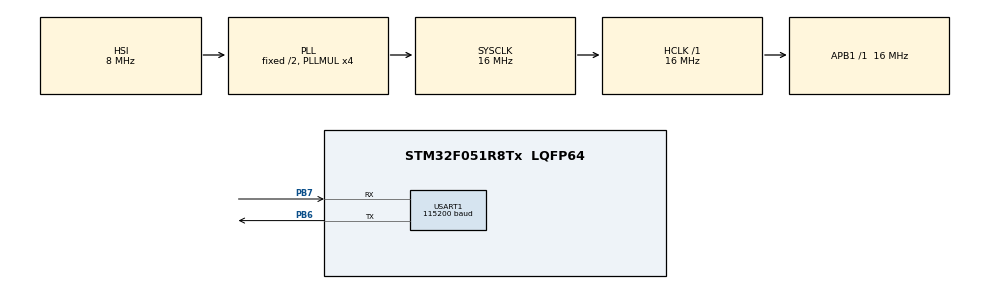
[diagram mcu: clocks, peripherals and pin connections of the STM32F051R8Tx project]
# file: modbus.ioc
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Mcu.Family=STM32F0
Dma.USART1_TX.1.Instance=DMA1_Channel2
Dma.USART1_RX.0.PeriphDataAlignment=DMA_PDATAALIGN_BYTE
Dma.USART1_TX.1.MemInc=DMA_MINC_ENABLE
USART1.BaudRate=115200
TIM6.Prescaler=15
VP_TIM6_VS_ClockSourceINT.Mode=Enable_Timer
RCC.SYSCLKSource=RCC_SYSCLKSOURCE_PLLCLK
ProjectManager.StackSize=0x200
USART1.VirtualMode-Asynchronous=VM_ASYNC
VP_SYS_VS_tim3.Mode=TIM3
ProjectManager.TargetToolchain=STM32CubeIDE
Dma.USART1_RX.0.Direction=DMA_PERIPH_TO_MEMORY
RCC.HCLKFreq_Value=16000000
USART1.Parity=PARITY_NONE
PB6.Signal=USART1_TX
PB6.Mode=Asynchronous
RCC.AHBFreq_Value=16000000
Dma.USART1_RX.0.Priority=DMA_PRIORITY_LOW
Dma.USART1_RX.0.PeriphInc=DMA_PINC_DISABLE
Dma.USART1_TX.1.MemDataAlignment=DMA_MDATAALIGN_BYTE
board=custom
RCC.PLLMUL=RCC_PLL_MUL4
NVIC.TIM3_IRQn=true\:0\:0\:false\:false\:true\:false\:true
USART1.OverrunDisableParam=ADVFEATURE_OVERRUN_DISABLE
Dma.USART1_RX.0.MemDataAlignment=DMA_MDATAALIGN_BYTE
PB7.Signal=USART1_RX
TIM6.Period=1
Dma.USART1_RX.0.MemInc=DMA_MINC_ENABLE
Mcu.Name=STM32F051R8Tx
Dma.USART1_TX.1.PeriphDataAlignment=DMA_PDATAALIGN_BYTE
RCC.SYSCLKFreq_VALUE=16000000
Mcu.Package=LQFP64
NVIC.TimeBase=TIM3_IRQn
Dma.USART1_TX.1.Mode=DMA_NORMAL
PB7.Mode=Asynchronous
NVIC.TimeBaseIP=TIM3
ProjectManager.HeapSize=0x50
Dma.USART1_TX.1.PeriphInc=DMA_PINC_DISABLE
USART1.DMADisableonRxErrorParam=ADVFEATURE_DMA_DISABLEONRXERROR
NVIC.DMA1_Channel2_3_IRQn=true\:0\:0\:false\:false\:true\:false\:true
RCC.APB1TimFreq_Value=16000000
Dma.Request1=USART1_TX
Dma.USART1_RX.0.Mode=DMA_NORMAL
Dma.USART1_TX.1.Priority=DMA_PRIORITY_LOW
NVIC.USART1_IRQn=true\:0\:0\:false\:false\:true\:true\:true
Dma.Request0=USART1_RX
RCC.APB1Freq_Value=16000000
Dma.USART1_RX.0.Instance=DMA1_Channel3
Dma.USART1_TX.1.Direction=DMA_MEMORY_TO_PERIPH

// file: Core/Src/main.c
/* USER CODE BEGIN Header */
/**
 ******************************************************************************
 * @file           : main.c
 * @brief          : Main program body
 ******************************************************************************
 * @attention
 *
 * <h2><center>&copy; Copyright (c) 2021 STMicroelectronics.
 * All rights reserved.</center></h2>
 *
 * This software component is licensed by ST under BSD 3-Clause license,
 * the "License"; You may not use this file except in compliance with the
 * License. You may obtain a copy of the License at:
 *                        opensource.org/licenses/BSD-3-Clause
 *
 ******************************************************************************
 */
/* USER CODE END Header */
#include "main.h"
#include "dma.h"
#include "tim.h"
#include "usart.h"
#include "gpio.h"

/* USER CODE BEGIN Includes */

#include "modbus.h"

/* USER CODE END Includes */

void SystemClock_Config(void);

int main(void)
{

  /* MCU Configuration--------------------------------------------------------*/

  /* Reset of all peripherals, Initializes the Flash interface and the Systick. */
  HAL_Init();

  /* Configure the system clock */
  SystemClock_Config();

  /* Initialize all configured peripherals */
  MX_GPIO_Init();
  MX_DMA_Init();
  MX_USART1_UART_Init();
  MX_TIM6_Init();
  /* USER CODE BEGIN 2 */

  initModbus();
  HAL_UARTEx_ReceiveToIdle_DMA(&huart1, mbBuffer, ASCII_FRAME_SIZE);

  SetHoldingRegisterValue_s16(50, -9999);
  SetHoldingRegisterValue_u16(1, 9998);
  SetHoldingRegisterValue_u32(10, 66888);
  SetHoldingRegisterValue_s32(11, -66888);
  SetHoldingRegisterValue_f32(12, 10.2134f);

  SetInputRegisterValue_s16(17, -9999);
  SetInputRegisterValue_u16(12, 9998);
  SetInputRegisterValue_u32(20, 66888);
  SetInputRegisterValue_s32(19, -66888);
  SetInputRegisterValue_f32(15, 10.2134f);
  /* USER CODE END 2 */

  /* Infinite loop */
  /* USER CODE BEGIN WHILE */
  while (1)
  {
    //SetHoldingRegisterValue_u32(24, GetHoldingRegisterValue_u32(10));
    HAL_Delay(100);
    /* USER CODE END WHILE */

  }
}

void SystemClock_Config(void)
{
  RCC_OscInitTypeDef RCC_OscInitStruct = {0};
  RCC_ClkInitTypeDef RCC_ClkInitStruct = {0};
  RCC_PeriphCLKInitTypeDef PeriphClkInit = {0};

  /** Initializes the RCC Oscillators according to the specified parameters
  * in the RCC_OscInitTypeDef structure.
  */
  RCC_OscInitStruct.OscillatorType = RCC_OSCILLATORTYPE_HSI;
  RCC_OscInitStruct.HSIState = RCC_HSI_ON;
  RCC_OscInitStruct.HSICalibrationValue = RCC_HSICALIBRATION_DEFAULT;
  RCC_OscInitStruct.PLL.PLLState = RCC_PLL_ON;
  RCC_OscInitStruct.PLL.PLLSource = RCC_PLLSOURCE_HSI;
  RCC_OscInitStruct.PLL.PLLMUL = RCC_PLL_MUL4;
  RCC_OscInitStruct.PLL.PREDIV = RCC_PREDIV_DIV1;
  if (HAL_RCC_OscConfig(&RCC_OscInitStruct) != HAL_OK)
  {
    Error_Handler();
  }
  /** Initializes the CPU, AHB and APB buses clocks
  */
  RCC_ClkInitStruct.ClockType = RCC_CLOCKTYPE_HCLK|RCC_CLOCKTYPE_SYSCLK
                              |RCC_CLOCKTYPE_PCLK1;
  RCC_ClkInitStruct.SYSCLKSource = RCC_SYSCLKSOURCE_PLLCLK;
  RCC_ClkInitStruct.AHBCLKDivider = RCC_SYSCLK_DIV1;
  RCC_ClkInitStruct.APB1CLKDivider = RCC_HCLK_DIV1;

  if (HAL_RCC_ClockConfig(&RCC_ClkInitStruct, FLASH_LATENCY_0) != HAL_OK)
  {
    Error_Handler();
  }
  PeriphClkInit.PeriphClockSelection = RCC_PERIPHCLK_USART1;
  PeriphClkInit.Usart1ClockSelection = RCC_USART1CLKSOURCE_PCLK1;
  if (HAL_RCCEx_PeriphCLKConfig(&PeriphClkInit) != HAL_OK)
  {
    Error_Handler();
  }
}

/* USER CODE BEGIN 4 */

/***********************************************************
 * Function name:HAL_UARTEx_RxEventCallback(UART_HandleTypeDef *huart, uint16_t Size)
 * Description: a call back that is run when data is received from port
 * Parameter huart :port to which data is received from and send to
 * Parameter size : length of received data
 * Return value:None
 * Remarks:None
 ***********************************************************/
void HAL_UARTEx_RxEventCallback(UART_HandleTypeDef *huart, uint16_t Size)
{
  uint8_t responseLength;
  responseLength=execute_modbus_command(mbBuffer, Size);
  if(responseLength>0)
	  HAL_UART_Transmit_DMA(&huart1, sendBuffer, responseLength);
  HAL_UARTEx_ReceiveToIdle_DMA(&huart1, mbBuffer, ASCII_FRAME_SIZE);
}

void HAL_UART_ErrorCallback(UART_HandleTypeDef *huart){
	HAL_UARTEx_ReceiveToIdle_DMA(&huart1, mbBuffer, ASCII_FRAME_SIZE);

}
/* USER CODE END 4 */

 /**
  * @brief  Period elapsed callback in non blocking mode
  * @note   This function is called  when TIM3 interrupt took place, inside
  * HAL_TIM_IRQHandler(). It makes a direct call to HAL_IncTick() to increment
  * a global variable "uwTick" used as application time base.
  * @param  htim : TIM handle
  * @retval None
  */
void HAL_TIM_PeriodElapsedCallback(TIM_HandleTypeDef *htim)
{
  if (htim->Instance == TIM3) {
    HAL_IncTick();
  }
}

void Error_Handler(void)
{
  __disable_irq();
  while (1)
  {
  }
}

/************************ (C) COPYRIGHT STMicroelectronics *****END OF FILE****/
